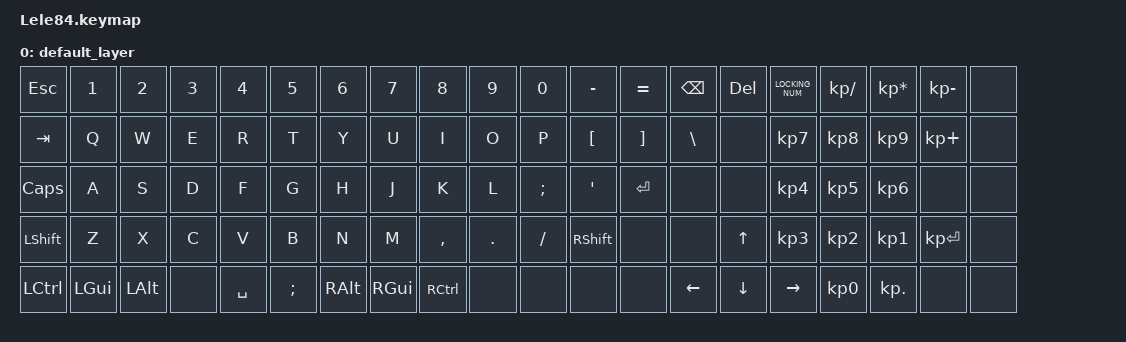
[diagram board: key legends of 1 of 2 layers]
/*
 * Copyright (c) 2020 The ZMK Contributors
 *
 * SPDX-License-Identifier: MIT
 */

#include <behaviors.dtsi>
#include <dt-bindings/zmk/keys.h>
#include <dt-bindings/zmk/bt.h>

/ {
	keymap0: keymap {
		compatible = "zmk,keymap";

		default_layer {
// ------------------------------------------------------------------------------------------
// | ESC |  1  |  2  |  3  |  4  |  5  |  6  |  7  |  8  |  9  |  0  |  -  |  =  |   BKSP   |
// | TAB  |  Q  |  W  |  E  |  R  |  T  |  Y  |  U  |  I  |  O  |  P  |  [  |  ]  |    \    |
// | CAPS  |  A  |  S  |  D  |  F  |  G  |  H  |  J  |  K  |  L  |  ;  |  '  |     ENTER    |
// |  SHIFT  |  Z  |  X  |  C  |  V  |  B  |  N  |  M  |  ,  |  .  |  /  |      SHIFT       |
// |  CTL  |  WIN  |  ALT  |            SPACE               | ALT | MO(1) |  WIN  | CTRL    |
// ------------------------------------------------------------------------------------------
			bindings = <
	&kp ESC &kp N1 &kp N2 &kp N3 &kp N4 &kp N5 &kp N6 &kp N7 &kp   N8  &kp  N9 &kp  N0  &kp MINUS &kp EQUAL &kp BSPC  &kp DELETE                             &kp LOCKING_NUM &kp KP_DIVIDE &kp KP_MULTIPLY &kp KP_MINUS &none
	&kp TAB  &kp Q  &kp W  &kp E  &kp R  &kp T  &kp Y  &kp U  &kp   I   &kp  O  &kp   P  &kp LBKT &kp RBKT  &kp BSLH  &none                                  &kp KP_NUMBER_7 &kp KP_NUMBER_8 &kp KP_NUMBER_9 &kp KP_PLUS &none
	&kp CLCK  &kp A  &kp S  &kp D  &kp F  &kp G  &kp H  &kp J  &kp   K   &kp  L  &kp SEMI &kp SQT     &kp RET   &none  &none                                 &kp KP_NUMBER_4 &kp KP_NUMBER_5 &kp KP_NUMBER_6 &none       &none
	&kp LSHFT  &kp Z  &kp X  &kp C  &kp V  &kp B  &kp N  &kp M  &kp COMMA &kp DOT &kp FSLH   &kp RSHFT  &none  &none                         &kp UP_ARROW    &kp KP_NUMBER_3 &kp KP_NUMBER_2 &kp KP_NUMBER_1 &kp KP_ENTER &none
	&kp LCTRL &kp LGUI &kp LALT  &none    &kp SPACE    &kp SEMI   &kp  RALT  &kp  RGUI  &kp  RCTRL &none  &none &none  &none&kp LEFT_ARROW   &kp DOWN_ARROW   &kp RIGHT_ARROW &kp KP_NUMBER_0 &kp KP_DOT &none            &none
			>;
		};

		fn_layer {
			bindings = <
&kp GRAVE  &kp F1     &kp F2     &kp F3     &kp F4     &kp F5     &kp F6     &kp F7     &kp F8     &kp F9     &kp F10    &kp F11    &kp F12    &bootloader
&trans         &bt BT_CLR &none      &none      &none      &none      &none      &none      &none      &none      &none      &none      &none      &reset
&trans           &bt BT_SEL 0 &bt BT_SEL 1 &bt BT_SEL 2 &bt BT_SEL 3 &bt BT_SEL 4 &kp LEFT   &kp DOWN   &kp UP   &kp RIGHT   &none      &none      &trans
&trans                &none      &none      &none      &none      &none      &none      &none      &none      &none      &none      &trans
&trans       &trans       &trans       &trans                                                                     &trans     &trans     &trans     &trans
			>;
		};
	};
};
